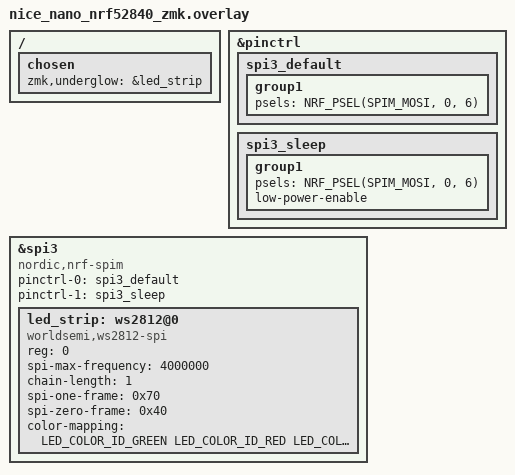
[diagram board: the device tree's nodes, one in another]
#include <dt-bindings/led/led.h>

// Dummy 1-pixel LED strip so &rgb_ug behaviors compile and forward to
// peripherals over BLE split. No physical LED is connected; SPI output
// on P0.06 is harmless. chain-length must be >= 1 to avoid division-by-zero
// in the swirl effect.

&pinctrl {
    spi3_default: spi3_default {
        group1 {
            psels = <NRF_PSEL(SPIM_MOSI, 0, 6)>;
        };
    };
    spi3_sleep: spi3_sleep {
        group1 {
            psels = <NRF_PSEL(SPIM_MOSI, 0, 6)>;
            low-power-enable;
        };
    };
};

&spi3 {
    compatible = "nordic,nrf-spim";
    status = "okay";
    pinctrl-0 = <&spi3_default>;
    pinctrl-1 = <&spi3_sleep>;
    pinctrl-names = "default", "sleep";

    led_strip: ws2812@0 {
        compatible = "worldsemi,ws2812-spi";
        reg = <0>;
        spi-max-frequency = <4000000>;
        chain-length = <1>;
        spi-one-frame = <0x70>;
        spi-zero-frame = <0x40>;
        color-mapping = <LED_COLOR_ID_GREEN LED_COLOR_ID_RED LED_COLOR_ID_BLUE>;
    };
};

/ {
    chosen {
        zmk,underglow = &led_strip;
    };
};
